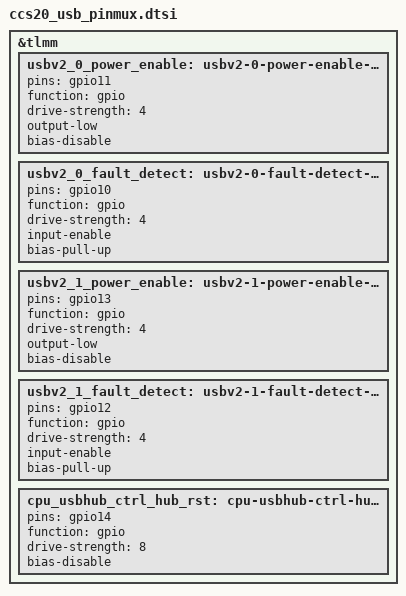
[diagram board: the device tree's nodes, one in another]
/*
 * Template A (fabricated): 4-space indent, flat '-state' nodes, no mux/config split.
 * Only this FORMAT should be copied into the output - none of the pins below may appear in it.
 */

/*
 * USB pin states for CCS20 - generated by usb_dts_tool from the PinMux workbook.
 * Every NEEDS REVIEW comment is an open decision; nothing marked so is verified.
 * Format: learned from the template 'template_A_spaces_flat.dtsi'.
 */

&tlmm {
    usbv2_0_power_enable: usbv2-0-power-enable-state {
        pins = "gpio11";
        function = "gpio";
        drive-strength = <4>;
        output-low;
        /* NEEDS REVIEW: level inferred as 'regulator OFF at boot' - matches the 2 accepted examples, not derivable from Excel; confirm */
        bias-disable;
    };

    usbv2_0_fault_detect: usbv2-0-fault-detect-state {
        pins = "gpio10";
        function = "gpio";
        drive-strength = <4>;
        input-enable;
        bias-pull-up;
    };

    usbv2_1_power_enable: usbv2-1-power-enable-state {
        pins = "gpio13";
        function = "gpio";
        drive-strength = <4>;
        output-low;
        /* NEEDS REVIEW: level inferred as 'regulator OFF at boot' - matches the 2 accepted examples, not derivable from Excel; confirm */
        bias-disable;
    };

    usbv2_1_fault_detect: usbv2-1-fault-detect-state {
        pins = "gpio12";
        function = "gpio";
        drive-strength = <4>;
        input-enable;
        bias-pull-up;
    };

    cpu_usbhub_ctrl_hub_rst: cpu-usbhub-ctrl-hub-rst-state {
        pins = "gpio14";
        function = "gpio";
        drive-strength = <8>;
        /* NEEDS REVIEW: output pin - add output-high or output-low per hardware design (level is not derivable from Excel) */
        bias-disable;
    };
};
